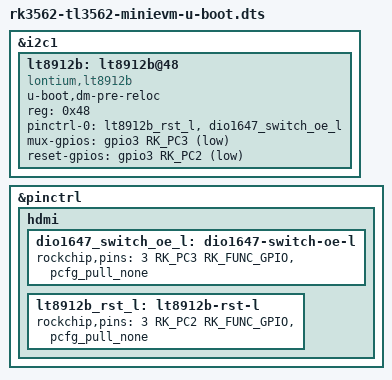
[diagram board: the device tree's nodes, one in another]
// SPDX-License-Identifier: (GPL-2.0+ OR MIT)
/*
 * Copyright (c) 2022 Rockchip Electronics Co., Ltd.
 * Copyright (c) 2026 flippy (flippy@sina.com)
 *
 */

#include "rk3562-tl3562-minievm.dts"

&i2c1 {
	/* LT8912B driver for u-boot, not for kernel! */
	lt8912b: lt8912b@48 {
		u-boot,dm-pre-reloc;
		compatible = "lontium,lt8912b";
		reg = <0x48>;

		pinctrl-names = "default";
		pinctrl-0 = <&lt8912b_rst_l &dio1647_switch_oe_l>;

		mux-gpios = <&gpio3 RK_PC3 GPIO_ACTIVE_LOW>;	  
		reset-gpios = <&gpio3 RK_PC2 GPIO_ACTIVE_LOW>;
		
		status = "okay";
	};
};

&pinctrl {
	hdmi {
		dio1647_switch_oe_l: dio1647-switch-oe-l {
			rockchip,pins = <3 RK_PC3 RK_FUNC_GPIO &pcfg_pull_none>;
		};

		lt8912b_rst_l: lt8912b-rst-l {
			rockchip,pins = <3 RK_PC2 RK_FUNC_GPIO &pcfg_pull_none>;
		};
	};
};
